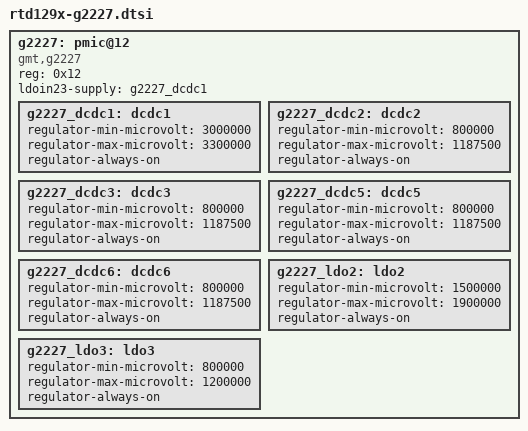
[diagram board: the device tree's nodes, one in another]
// SPDX-License-Identifier: (GPL-2.0-or-later OR BSD-2-Clause)
/*
 * Copyright (c) 2017 Andreas Färber
 */

	g2227: pmic@12 {
		compatible = "gmt,g2227";
		reg = <0x12>;
		ldoin23-supply = <&g2227_dcdc1>;

		g2227_dcdc1: dcdc1 {
			regulator-min-microvolt = <3000000>;
			regulator-max-microvolt = <3300000>;
			regulator-always-on;
		};

		g2227_dcdc2: dcdc2 {
			regulator-min-microvolt = < 800000>;
			regulator-max-microvolt = <1187500>;
			regulator-always-on;
		};

		g2227_dcdc3: dcdc3 {
			regulator-min-microvolt = < 800000>;
			regulator-max-microvolt = <1187500>;
			regulator-always-on;
		};

		g2227_dcdc5: dcdc5 {
			regulator-min-microvolt = < 800000>;
			regulator-max-microvolt = <1187500>;
			regulator-always-on;
		};

		g2227_dcdc6: dcdc6 {
			regulator-min-microvolt = < 800000>;
			regulator-max-microvolt = <1187500>;
			regulator-always-on;
		};

		g2227_ldo2: ldo2 {
			regulator-min-microvolt = <1500000>;
			regulator-max-microvolt = <1900000>;
			regulator-always-on;
		};

		g2227_ldo3: ldo3 {
			regulator-min-microvolt = < 800000>;
			regulator-max-microvolt = <1200000>;
			regulator-always-on;
		};
	};
